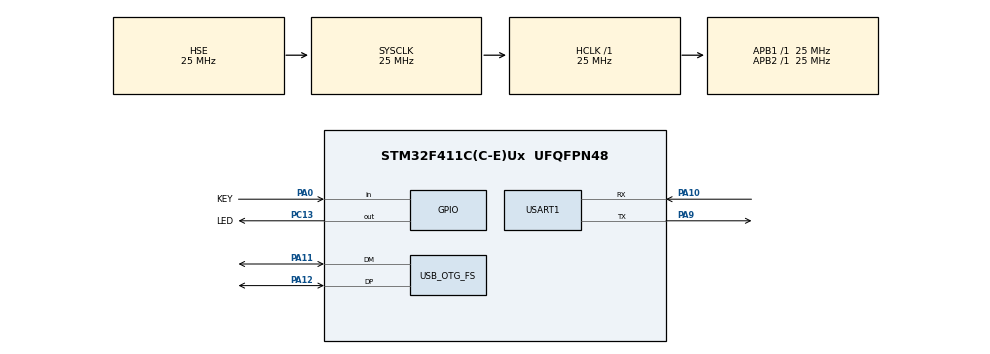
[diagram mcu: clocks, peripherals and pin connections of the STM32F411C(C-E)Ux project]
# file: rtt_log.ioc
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Mcu.Family=STM32F4
Mcu.Name=STM32F411C(C-E)Ux
Mcu.Package=UFQFPN48
NVIC.OTG_FS_IRQn=true\:0\:0\:false\:false\:true\:false\:true\:true
NVIC.PriorityGroup=NVIC_PRIORITYGROUP_4
NVIC.USART1_IRQn=true\:0\:0\:false\:false\:true\:true\:true\:true
PA0-WKUP.GPIO_Label=KEY
PA0-WKUP.Signal=GPIO_Input
PA10.Mode=Asynchronous
PA10.Signal=USART1_RX
PA11.Mode=Device_Only
PA11.Signal=USB_OTG_FS_DM
PA12.Mode=Device_Only
PA12.Signal=USB_OTG_FS_DP
PA13.Mode=Serial_Wire
PA13.Signal=SYS_JTMS-SWDIO
PA14.Mode=Serial_Wire
PA14.Signal=SYS_JTCK-SWCLK
PA9.Mode=Asynchronous
PA9.Signal=USART1_TX
PC13-ANTI_TAMP.GPIO_Label=LED
PC13-ANTI_TAMP.PinState=GPIO_PIN_SET
PC13-ANTI_TAMP.Signal=GPIO_Output
PC14-OSC32_IN.Mode=LSE-External-Oscillator
PC14-OSC32_IN.Signal=RCC_OSC32_IN
PC15-OSC32_OUT.Mode=LSE-External-Oscillator
PC15-OSC32_OUT.Signal=RCC_OSC32_OUT
PH0\ -\ OSC_IN.Mode=HSE-External-Oscillator
PH0\ -\ OSC_IN.Signal=RCC_OSC_IN
PH1\ -\ OSC_OUT.Mode=HSE-External-Oscillator
PH1\ -\ OSC_OUT.Signal=RCC_OSC_OUT
ProjectManager.HeapSize=0x800
ProjectManager.StackSize=0x400
ProjectManager.TargetToolchain=MDK-ARM V5.32
RCC.48MHZClocksFreq_Value=48000000
RCC.AHBFreq_Value=25000000
RCC.APB1Freq_Value=25000000
RCC.APB1TimFreq_Value=25000000
RCC.APB2Freq_Value=25000000
RCC.APB2TimFreq_Value=25000000
RCC.CortexFreq_Value=25000000
RCC.HCLKFreq_Value=25000000
RCC.HSE_VALUE=25000000
RCC.HSI_VALUE=16000000
RCC.PLLM=15
RCC.PLLN=144
RCC.PLLQ=5
RCC.RCC_RTC_Clock_Source=RCC_RTCCLKSOURCE_LSE
RCC.RCC_RTC_Clock_SourceVirtual=RCC_RTCCLKSOURCE_LSE
RCC.SYSCLKFreq_VALUE=25000000
RCC.SYSCLKSource=RCC_SYSCLKSOURCE_HSE
RCC.VCOOutputFreq_Value=240000000
USART1.VirtualMode=VM_ASYNC
USB_DEVICE.CLASS_NAME_FS=CDC
USB_DEVICE.VirtualMode=Cdc
USB_DEVICE.VirtualModeFS=Cdc_FS
USB_OTG_FS.VirtualMode=Device_Only
VP_RTC_VS_RTC_Activate.Mode=RTC_Enabled
VP_USB_DEVICE_VS_USB_DEVICE_CDC_FS.Mode=CDC_FS
board=custom

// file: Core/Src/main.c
/* USER CODE BEGIN Header */
/**
  ******************************************************************************
  * @file           : main.c
  * @brief          : Main program body
  ******************************************************************************
  * @attention
  *
  * Copyright (c) 2024 STMicroelectronics.
  * All rights reserved.
  *
  * This software is licensed under terms that can be found in the LICENSE file
  * in the root directory of this software component.
  * If no LICENSE file comes with this software, it is provided AS-IS.
  *
  ******************************************************************************
  */
/* USER CODE END Header */
#include "main.h"
#include "rtc.h"
#include "usart.h"
#include "usb_device.h"
#include "gpio.h"

/* USER CODE BEGIN Includes */
#include "SEGGER_RTT.h"
#include "elog.h"
#include "user_rtt_printf.h"

/* USER CODE END Includes */

void SystemClock_Config(void);

/* USER CODE BEGIN 0 */
void test_elog(void) {
    /* test log output for all level */
    log_a("Hello EasyLogger!");
    log_e("Hello EasyLogger!");
    log_w("Hello EasyLogger!");
    log_i("Hello EasyLogger!");
    log_d("Hello EasyLogger!");
    log_v("Hello EasyLogger!");
//    elog_raw("Hello EasyLogger!");
}
/* USER CODE END 0 */

int main(void)
{

  /* MCU Configuration--------------------------------------------------------*/

  /* Reset of all peripherals, Initializes the Flash interface and the Systick. */
  HAL_Init();

  /* Configure the system clock */
  SystemClock_Config();

  /* Initialize all configured peripherals */
  MX_GPIO_Init();
  MX_RTC_Init();
  MX_USART1_UART_Init();
  MX_USB_DEVICE_Init();
  /* USER CODE BEGIN 2 */
  /************Use RTT****************/
  //SEGGER_RTT_Init();

  /************Use Easylog************/
  /* close printf buffer */
  // setbuf(stdout, NULL);
  /* initialize EasyLogger */
  // elog_init();
  /* set EasyLogger log format */
  // elog_set_fmt(ELOG_LVL_ASSERT, ELOG_FMT_ALL);
  // elog_set_fmt(ELOG_LVL_ERROR, ELOG_FMT_LVL | ELOG_FMT_TAG | ELOG_FMT_TIME);
  // elog_set_fmt(ELOG_LVL_WARN, ELOG_FMT_LVL | ELOG_FMT_TAG | ELOG_FMT_TIME);
  // elog_set_fmt(ELOG_LVL_INFO, ELOG_FMT_LVL | ELOG_FMT_TAG | ELOG_FMT_TIME);
  // elog_set_fmt(ELOG_LVL_DEBUG, ELOG_FMT_ALL & ~ELOG_FMT_FUNC);
  // elog_set_fmt(ELOG_LVL_VERBOSE, ELOG_FMT_ALL & ~ELOG_FMT_FUNC);
  /* start EasyLogger */
  // elog_start();

  /* USER CODE END 2 */

  /* Infinite loop */
  /* USER CODE BEGIN WHILE */
  while (1)
  {
    /* rtt printf */
    // SEGGER_RTT_printf(0, "Hello world!\r\n");
    // HAL_Delay(1000);

    /* test easylogger output */
    // test_elog();
    // HAL_Delay(1000);

    /* 封装RTT库接口 */
    LOGI("[%d] Hello world!", HAL_GetTick());
    HAL_Delay(1000);

    /* USER CODE END WHILE */

  }
}

void SystemClock_Config(void)
{
  RCC_OscInitTypeDef RCC_OscInitStruct = {0};
  RCC_ClkInitTypeDef RCC_ClkInitStruct = {0};

  /** Configure the main internal regulator output voltage
  */
  __HAL_RCC_PWR_CLK_ENABLE();
  __HAL_PWR_VOLTAGESCALING_CONFIG(PWR_REGULATOR_VOLTAGE_SCALE1);

  /** Initializes the RCC Oscillators according to the specified parameters
  * in the RCC_OscInitTypeDef structure.
  */
  RCC_OscInitStruct.OscillatorType = RCC_OSCILLATORTYPE_HSE|RCC_OSCILLATORTYPE_LSE;
  RCC_OscInitStruct.HSEState = RCC_HSE_ON;
  RCC_OscInitStruct.LSEState = RCC_LSE_ON;
  RCC_OscInitStruct.PLL.PLLState = RCC_PLL_ON;
  RCC_OscInitStruct.PLL.PLLSource = RCC_PLLSOURCE_HSE;
  RCC_OscInitStruct.PLL.PLLM = 15;
  RCC_OscInitStruct.PLL.PLLN = 144;
  RCC_OscInitStruct.PLL.PLLP = RCC_PLLP_DIV2;
  RCC_OscInitStruct.PLL.PLLQ = 5;
  if (HAL_RCC_OscConfig(&RCC_OscInitStruct) != HAL_OK)
  {
    Error_Handler();
  }

  /** Initializes the CPU, AHB and APB buses clocks
  */
  RCC_ClkInitStruct.ClockType = RCC_CLOCKTYPE_HCLK|RCC_CLOCKTYPE_SYSCLK
                              |RCC_CLOCKTYPE_PCLK1|RCC_CLOCKTYPE_PCLK2;
  RCC_ClkInitStruct.SYSCLKSource = RCC_SYSCLKSOURCE_HSE;
  RCC_ClkInitStruct.AHBCLKDivider = RCC_SYSCLK_DIV1;
  RCC_ClkInitStruct.APB1CLKDivider = RCC_HCLK_DIV1;
  RCC_ClkInitStruct.APB2CLKDivider = RCC_HCLK_DIV1;

  if (HAL_RCC_ClockConfig(&RCC_ClkInitStruct, FLASH_LATENCY_0) != HAL_OK)
  {
    Error_Handler();
  }
}

void Error_Handler(void)
{
  __disable_irq();
  while (1)
  {
  }
}
